AUTOSAR XML (schema 4-0-3)
standard types defined: Boolean, UInt16, UInt32
package /AUTOSAR_Platform/DataConstrs
  range DC_Boolean: raw 0..1
  range DC_UInt16: raw 0..65535
package /PATAC/Facility/DataTypes/Implementation
  compu method COMPU_Boolean: 0=FALSE, 1=TRUE
  unit NoUnit: factor-si-to-unit=1, offset-si-to-unit=0
package /PATAC/MSM/ComponentTypes
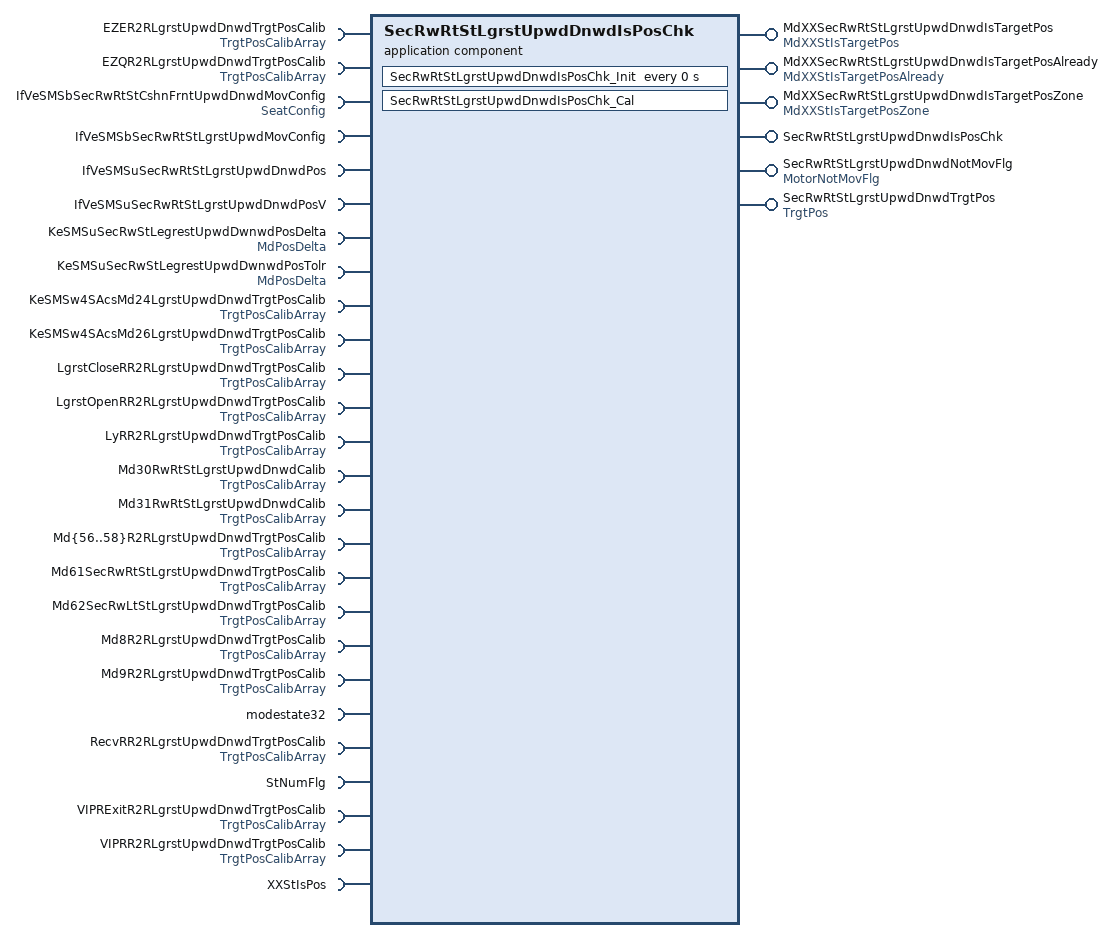
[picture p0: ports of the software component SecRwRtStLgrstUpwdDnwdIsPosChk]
  application sw component type SecRwRtStLgrstUpwdDnwdIsPosChk
    6 x provide port:
      MdXXSecRwRtStLgrstUpwdDnwdIsTargetPos: nonqueued-sender-com-spec=data-element=MdXXStIsTargetPos/Val, provided-interface=MdXXStIsTargetPos
      MdXXSecRwRtStLgrstUpwdDnwdIsTargetPosAlready: nonqueued-sender-com-spec=data-element=MdXXStIsTargetPosAlready/Val, provided-interface=MdXXStIsTargetPosAlready
      MdXXSecRwRtStLgrstUpwdDnwdIsTargetPosZone: nonqueued-sender-com-spec=data-element=MdXXStIsTargetPosZone/Val, provided-interface=MdXXStIsTargetPosZone
      SecRwRtStLgrstUpwdDnwdIsPosChk: server-com-spec{operation=Cal, queue-length=1}, provided-interface=SecRwRtStLgrstUpwdDnwdIsPosChk
      SecRwRtStLgrstUpwdDnwdNotMovFlg: nonqueued-sender-com-spec{data-element=MotorNotMovFlg/Val, init-value=0}, provided-interface=MotorNotMovFlg
      SecRwRtStLgrstUpwdDnwdTrgtPos: nonqueued-sender-com-spec{data-element=TrgtPos/Val, init-value=4095}, provided-interface=TrgtPos
    28 x require port:
      EZER2RLgrstUpwdDnwdTrgtPosCalib: nonqueued-receiver-com-spec{data-element=TrgtPosArray, filter=data-filter-type=ALWAYS, init-value=[4095, 4095, 4095]}, required-interface=TrgtPosCalibArray
      EZQR2RLgrstUpwdDnwdTrgtPosCalib: nonqueued-receiver-com-spec{data-element=TrgtPosArray, filter=data-filter-type=ALWAYS, init-value=[4095, 4095, 4095]}, required-interface=TrgtPosCalibArray
      IfVeSMSbSecRwRtStCshnFrntUpwdDnwdMovConfig: nonqueued-receiver-com-spec{data-element=SeatConfig/Val, filter=data-filter-type=ALWAYS, init-value=0}, required-interface=SeatConfig
      IfVeSMSbSecRwRtStLgrstUpwdMovConfig: nonqueued-receiver-com-spec{data-element=IfVeSMSbSecRwRtStLgrstUpwdMovConfig/Val, filter=data-filter-type=ALWAYS, init-value=0}, required-interface=IfVeSMSbSecRwRtStLgrstUpwdMovConfig
      IfVeSMSuSecRwRtStLgrstUpwdDnwdPos: nonqueued-receiver-com-spec{data-element=IfVeSMSuSecRwRtStLgrstUpwdDnwdPos/Val, filter=data-filter-type=ALWAYS, init-value=0}, required-interface=IfVeSMSuSecRwRtStLgrstUpwdDnwdPos
      IfVeSMSuSecRwRtStLgrstUpwdDnwdPosV: nonqueued-receiver-com-spec{data-element=IfVeSMSuSecRwRtStLgrstUpwdDnwdPosV/Val, filter=data-filter-type=ALWAYS, init-value=0}, required-interface=IfVeSMSuSecRwRtStLgrstUpwdDnwdPosV
      KeSMSuSecRwStLegrestUpwdDwnwdPosDelta: parameter-require-com-spec{init-value=150, parameter=Val}, required-interface=MdPosDelta
      KeSMSuSecRwStLegrestUpwdDwnwdPosTolr: parameter-require-com-spec{init-value=150, parameter=Val}, required-interface=MdPosDelta
      KeSMSw4SAcsMd24LgrstUpwdDnwdTrgtPosCalib: nonqueued-receiver-com-spec{data-element=TrgtPosArray, filter=data-filter-type=ALWAYS, init-value=[4095, 4095, 4095]}, required-interface=TrgtPosCalibArray
      KeSMSw4SAcsMd26LgrstUpwdDnwdTrgtPosCalib: nonqueued-receiver-com-spec{data-element=TrgtPosArray, filter=data-filter-type=ALWAYS, init-value=[4095, 4095, 4095]}, required-interface=TrgtPosCalibArray
      LgrstCloseRR2RLgrstUpwdDnwdTrgtPosCalib: nonqueued-receiver-com-spec{data-element=TrgtPosArray, filter=data-filter-type=ALWAYS, init-value=[4095, 4095, 4095]}, required-interface=TrgtPosCalibArray
      LgrstOpenRR2RLgrstUpwdDnwdTrgtPosCalib: nonqueued-receiver-com-spec{data-element=TrgtPosArray, filter=data-filter-type=ALWAYS, init-value=[4095, 4095, 4095]}, required-interface=TrgtPosCalibArray
      LyRR2RLgrstUpwdDnwdTrgtPosCalib: nonqueued-receiver-com-spec{data-element=TrgtPosArray, filter=data-filter-type=ALWAYS, init-value=[4095, 4095, 4095]}, required-interface=TrgtPosCalibArray
      Md30RwRtStLgrstUpwdDnwdCalib: nonqueued-receiver-com-spec{data-element=TrgtPosArray, filter=data-filter-type=ALWAYS, init-value=[4095, 4095, 4095]}, required-interface=TrgtPosCalibArray
      Md31RwRtStLgrstUpwdDnwdCalib: nonqueued-receiver-com-spec{data-element=TrgtPosArray, filter=data-filter-type=ALWAYS, init-value=[4095, 4095, 4095]}, required-interface=TrgtPosCalibArray
      Md{56..58}R2RLgrstUpwdDnwdTrgtPosCalib: nonqueued-receiver-com-spec{data-element=TrgtPosArray, filter=data-filter-type=ALWAYS, init-value=[4095, 4095, 4095]}, required-interface=TrgtPosCalibArray
      Md61SecRwRtStLgrstUpwdDnwdTrgtPosCalib: nonqueued-receiver-com-spec{data-element=TrgtPosArray, filter=data-filter-type=ALWAYS, init-value=[4095, 4095, 4095]}, required-interface=TrgtPosCalibArray
      Md62SecRwLtStLgrstUpwdDnwdTrgtPosCalib: nonqueued-receiver-com-spec{data-element=TrgtPosArray, filter=data-filter-type=ALWAYS, init-value=[4095, 4095, 4095]}, required-interface=TrgtPosCalibArray
      Md8R2RLgrstUpwdDnwdTrgtPosCalib: nonqueued-receiver-com-spec{data-element=TrgtPosArray, filter=data-filter-type=ALWAYS, init-value=[4095, 4095, 4095]}, required-interface=TrgtPosCalibArray
      Md9R2RLgrstUpwdDnwdTrgtPosCalib: nonqueued-receiver-com-spec{data-element=TrgtPosArray, filter=data-filter-type=ALWAYS, init-value=[4095, 4095, 4095]}, required-interface=TrgtPosCalibArray
      modestate32: nonqueued-receiver-com-spec{data-element=modestate32/Val, filter=data-filter-type=ALWAYS, init-value=0}, required-interface=modestate32
      RecvRR2RLgrstUpwdDnwdTrgtPosCalib: nonqueued-receiver-com-spec{data-element=TrgtPosArray, filter=data-filter-type=ALWAYS, init-value=[4095, 4095, 4095]}, required-interface=TrgtPosCalibArray
      StNumFlg: required-interface=StNumFlg
        required-com-specs:
          data-element=Is4s, filter=data-filter-type=ALWAYS, init-value=0
          data-element=Is6s, filter=data-filter-type=ALWAYS, init-value=0
          data-element=Is6s7s, filter=data-filter-type=ALWAYS, init-value=0
          data-element=Is7s, filter=data-filter-type=ALWAYS, init-value=0
      VIPRExitR2RLgrstUpwdDnwdTrgtPosCalib: nonqueued-receiver-com-spec{data-element=TrgtPosArray, filter=data-filter-type=ALWAYS, init-value=[4095, 4095, 4095]}, required-interface=TrgtPosCalibArray
      VIPRR2RLgrstUpwdDnwdTrgtPosCalib: nonqueued-receiver-com-spec{data-element=TrgtPosArray, filter=data-filter-type=ALWAYS, init-value=[4095, 4095, 4095]}, required-interface=TrgtPosCalibArray
      XXStIsPos: client-com-spec=Get, required-interface=XXStIsPos
    behavior SecRwRtStLgrstUpwdDnwdIsPosChk_InternalBehavior
      operation invoked event OIT_SecRwRtStLgrstUpwdDnwdIsPosChk_Cal_SecRwRtStLgrstUpwdDnwdIsPosChk_Cal: start-on-event=SecRwRtStLgrstUpwdDnwdIsPosChk_Cal, operation=SecRwRtStLgrstUpwdDnwdIsPosChk.Cal
      timing event SecRwRtStLgrstUpwdDnwdIsPosChk_InitEvent: start-on-event=SecRwRtStLgrstUpwdDnwdIsPosChk_Init, period=0
      runnable SecRwRtStLgrstUpwdDnwdIsPosChk_Cal
        data-receive-point-by-arguments:
          28 x access:
            REC_EZER2RLgrstUpwdDnwdTrgtPosCalib_TrgtPosArray: accessed-variable=EZER2RLgrstUpwdDnwdTrgtPosCalib.TrgtPosArray
            REC_EZQR2RLgrstUpwdDnwdTrgtPosCalib_TrgtPosArray: accessed-variable=EZQR2RLgrstUpwdDnwdTrgtPosCalib.TrgtPosArray
            REC_IfVeSMSbSecRwRtStCshnFrntUpwdDnwdMovConfig_Val: accessed-variable=IfVeSMSbSecRwRtStCshnFrntUpwdDnwdMovConfig.Val
            REC_IfVeSMSbSecRwRtStLgrstUpwdMovConfig_Val: accessed-variable=IfVeSMSbSecRwRtStLgrstUpwdMovConfig.Val
            REC_IfVeSMSuSecRwRtStLgrstUpwdDnwdPos_Val: accessed-variable=IfVeSMSuSecRwRtStLgrstUpwdDnwdPos.Val
            REC_IfVeSMSuSecRwRtStLgrstUpwdDnwdPosV_Val: accessed-variable=IfVeSMSuSecRwRtStLgrstUpwdDnwdPosV.Val
            REC_KeSMSw4SAcsMd24LgrstUpwdDnwdTrgtPosCalib_TrgtPosArray: accessed-variable=KeSMSw4SAcsMd24LgrstUpwdDnwdTrgtPosCalib.TrgtPosArray
            REC_KeSMSw4SAcsMd26LgrstUpwdDnwdTrgtPosCalib_TrgtPosArray: accessed-variable=KeSMSw4SAcsMd26LgrstUpwdDnwdTrgtPosCalib.TrgtPosArray
            REC_LgrstCloseRR2RLgrstUpwdDnwdTrgtPosCalib_TrgtPosArray: accessed-variable=LgrstCloseRR2RLgrstUpwdDnwdTrgtPosCalib.TrgtPosArray
            REC_LgrstOpenRR2RLgrstUpwdDnwdTrgtPosCalib_TrgtPosArray: accessed-variable=LgrstOpenRR2RLgrstUpwdDnwdTrgtPosCalib.TrgtPosArray
            REC_LyRR2RLgrstUpwdDnwdTrgtPosCalib_TrgtPosArray: accessed-variable=LyRR2RLgrstUpwdDnwdTrgtPosCalib.TrgtPosArray
            REC_Md30RwRtStLgrstUpwdDnwdCalib_TrgtPosArray: accessed-variable=Md30RwRtStLgrstUpwdDnwdCalib.TrgtPosArray
            REC_Md31RwRtStLgrstUpwdDnwdCalib_TrgtPosArray: accessed-variable=Md31RwRtStLgrstUpwdDnwdCalib.TrgtPosArray
            REC_Md{56..58}R2RLgrstUpwdDnwdTrgtPosCalib_TrgtPosArray: accessed-variable=Md{56..58}R2RLgrstUpwdDnwdTrgtPosCalib.TrgtPosArray
            REC_Md61SecRwRtStLgrstUpwdDnwdTrgtPosCalib_TrgtPosArray: accessed-variable=Md61SecRwRtStLgrstUpwdDnwdTrgtPosCalib.TrgtPosArray
            REC_Md62SecRwLtStLgrstUpwdDnwdTrgtPosCalib_TrgtPosArray: accessed-variable=Md62SecRwLtStLgrstUpwdDnwdTrgtPosCalib.TrgtPosArray
            REC_Md8R2RLgrstUpwdDnwdTrgtPosCalib_TrgtPosArray: accessed-variable=Md8R2RLgrstUpwdDnwdTrgtPosCalib.TrgtPosArray
            REC_Md9R2RLgrstUpwdDnwdTrgtPosCalib_TrgtPosArray: accessed-variable=Md9R2RLgrstUpwdDnwdTrgtPosCalib.TrgtPosArray
            REC_modestate32_Val: accessed-variable=modestate32.Val
            REC_RecvRR2RLgrstUpwdDnwdTrgtPosCalib_TrgtPosArray: accessed-variable=RecvRR2RLgrstUpwdDnwdTrgtPosCalib.TrgtPosArray
            REC_StNumFlg_Is4s: accessed-variable=StNumFlg.Is4s
            REC_StNumFlg_Is6s: accessed-variable=StNumFlg.Is6s
            REC_StNumFlg_Is6s7s: accessed-variable=StNumFlg.Is6s7s
            REC_StNumFlg_Is7s: accessed-variable=StNumFlg.Is7s
            REC_VIPRExitR2RLgrstUpwdDnwdTrgtPosCalib_TrgtPosArray: accessed-variable=VIPRExitR2RLgrstUpwdDnwdTrgtPosCalib.TrgtPosArray
            REC_VIPRR2RLgrstUpwdDnwdTrgtPosCalib_TrgtPosArray: accessed-variable=VIPRR2RLgrstUpwdDnwdTrgtPosCalib.TrgtPosArray
        data-send-points:
          5 x access:
            SEND_MdXXSecRwRtStLgrstUpwdDnwdIsTargetPos_Val: accessed-variable=MdXXSecRwRtStLgrstUpwdDnwdIsTargetPos.Val
            SEND_MdXXSecRwRtStLgrstUpwdDnwdIsTargetPosAlready_Val: accessed-variable=MdXXSecRwRtStLgrstUpwdDnwdIsTargetPosAlready.Val
            SEND_MdXXSecRwRtStLgrstUpwdDnwdIsTargetPosZone_Val: accessed-variable=MdXXSecRwRtStLgrstUpwdDnwdIsTargetPosZone.Val
            SEND_SecRwRtStLgrstUpwdDnwdNotMovFlg_Val: accessed-variable=SecRwRtStLgrstUpwdDnwdNotMovFlg.Val
            SEND_SecRwRtStLgrstUpwdDnwdTrgtPos_Val: accessed-variable=SecRwRtStLgrstUpwdDnwdTrgtPos.Val
        parameter access PA_KeSMSuSecRwStLegrestUpwdDwnwdPosDelta_Val: accessed-parameter=KeSMSuSecRwStLegrestUpwdDwnwdPosDelta.Val
        parameter access PA_KeSMSuSecRwStLegrestUpwdDwnwdPosTolr_Val: accessed-parameter=KeSMSuSecRwStLegrestUpwdDwnwdPosTolr.Val
        sync call SC_XXStIsPos_Get: operation=XXStIsPos.Get, timeout=0
      runnable SecRwRtStLgrstUpwdDnwdIsPosChk_Init
        parameter access PA_KeSMSuSecRwStLegrestUpwdDwnwdPosDelta_Val: accessed-parameter=KeSMSuSecRwStLegrestUpwdDwnwdPosDelta.Val
        parameter access PA_KeSMSuSecRwStLegrestUpwdDwnwdPosTolr_Val: accessed-parameter=KeSMSuSecRwStLegrestUpwdDwnwdPosTolr.Val
  swc implementation SecRwRtStLgrstUpwdDnwdIsPosChk_Implementation: behavior=SecRwRtStLgrstUpwdDnwdIsPosChk_InternalBehavior
    code-descriptors:
      code Default: artifact-descriptors=autosar-engineering-object={short-label=Default, category=SWSRC}
package /PATAC/MSM/ModeAdjust/CalPortInterface
  parameter interface MdPosDelta
    parameter data prototype Val: sw-calibration-access=READ-WRITE, type=UInt16
package /PATAC/MSM/ModeAdjust/DataType
  impl type TrgtPosCalibArray: category=ARRAY, sw-calibration-access=READ-ONLY, type-emitter=RTE  # 0:pos 1:max 2:min
    element Element: array-size=3, array-size-semantics=FIXED-SIZE, implementation-data-type=UInt16, invalid-value=0
package /PATAC/MSM/ModeAdjust/Interfaces
  sender receiver interface IfVeSMSuSecRwRtStLgrstUpwdDnwdPosV: invalidation-policy{data-element=IfVeSMSuSecRwRtStLgrstUpwdDnwdPosV/Val, handle-invalid=DONT-INVALIDATE}
    data Val: type=Implementation/Boolean
package /PATAC/MSM/ModeAdjust/PortInterface
  client server interface SecRwRtStLgrstUpwdDnwdIsPosChk
    operation Cal
  client server interface XXStIsPos
    operation Get
      8 x arg, all with server-argument-impl-policy=USE-ARGUMENT-TYPE:
        PosV: type=DataTypes/Boolean, direction=IN
        Pos: type=UInt16, direction=IN
        CalibArray: type=TrgtPosCalibArray, direction=IN
        Delta: type=UInt16, direction=IN
        Tolr: type=UInt16, direction=IN
        IsPos: type=DataTypes/Boolean, direction=OUT
        IsPosZone: type=DataTypes/Boolean, direction=OUT
        IsPosAlready: type=DataTypes/Boolean, direction=OUT
  7 x sender receiver interface:
    MdXXStIsTargetPos: invalidation-policy{data-element=MdXXStIsTargetPos/Val, handle-invalid=DONT-INVALIDATE}
      data Val: type=UInt32
    MdXXStIsTargetPosAlready: invalidation-policy{data-element=MdXXStIsTargetPosAlready/Val, handle-invalid=DONT-INVALIDATE}
      data Val: type=UInt32
    MdXXStIsTargetPosZone: invalidation-policy{data-element=MdXXStIsTargetPosZone/Val, handle-invalid=DONT-INVALIDATE}
      data Val: type=UInt32
    modestate32: invalidation-policy{data-element=modestate32/Val, handle-invalid=DONT-INVALIDATE}
      data Val: type=UInt32
    MotorNotMovFlg: invalidation-policy{data-element=MotorNotMovFlg/Val, handle-invalid=DONT-INVALIDATE}
      data Val: type=Implementation/Boolean
    StNumFlg
      4 x data, all with type=Implementation/Boolean:
        Is4s
        Is6s
        Is6s7s
        Is7s
      invalidation-policys:
        data-element=Is4s, handle-invalid=DONT-INVALIDATE
        data-element=Is6s, handle-invalid=DONT-INVALIDATE
        data-element=Is6s7s, handle-invalid=DONT-INVALIDATE
        data-element=Is7s, handle-invalid=DONT-INVALIDATE
    TrgtPosCalibArray: invalidation-policy{data-element=TrgtPosArray, handle-invalid=DONT-INVALIDATE}
      data TrgtPosArray: type=TrgtPosCalibArray  # 0:Pos 1:Max 2:Min
package /PATAC/MSM/PortInterfaces
  4 x sender receiver interface:
    IfVeSMSbSecRwRtStLgrstUpwdMovConfig: invalidation-policy{data-element=IfVeSMSbSecRwRtStLgrstUpwdMovConfig/Val, handle-invalid=DONT-INVALIDATE}
      data Val: type=Implementation/Boolean
    IfVeSMSuSecRwRtStLgrstUpwdDnwdPos: invalidation-policy{data-element=IfVeSMSuSecRwRtStLgrstUpwdDnwdPos/Val, handle-invalid=DONT-INVALIDATE}
      data Val: type=UInt16
    SeatConfig: invalidation-policy{data-element=SeatConfig/Val, handle-invalid=DONT-INVALIDATE}
      data Val: type=Implementation/Boolean
    TrgtPos: invalidation-policy{data-element=TrgtPos/Val, handle-invalid=DONT-INVALIDATE}
      data Val: type=UInt16
